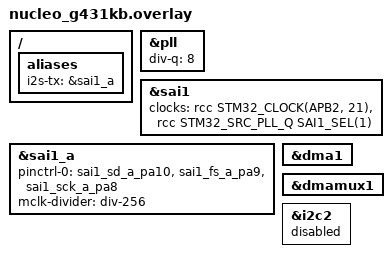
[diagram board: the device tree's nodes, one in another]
/*
 * Copyright (c) 2025 Mario Paja
 *
 * SPDX-License-Identifier: Apache-2.0
 */

/ {
	aliases {
		i2s-tx = &sai1_a;
	};
};

&pll {
	/* 44.1KHz (-0.03% Error) */
	div-q = <8>;
};

&sai1 {
	clocks = <&rcc STM32_CLOCK(APB2, 21)>,
		 <&rcc STM32_SRC_PLL_Q SAI1_SEL(1)>;
	clock-names = "sai_ck", "sai_ker_ck";
	status = "okay";
};

/* MCLK is not enabled */
/* SAI1_A MCLK (PB8) is not available on the Arduino Nano header */
&sai1_a {
	pinctrl-0 = <&sai1_sd_a_pa10 &sai1_fs_a_pa9 &sai1_sck_a_pa8>;
	pinctrl-names = "default";
	mclk-divider = "div-256";
	dma-names = "tx";
	status = "okay";
};

&dma1 {
	status = "okay";
};

&dmamux1 {
	status = "okay";
};

/* I2C2 SCL conflicts with SAI1_A FS */
/* I2C2 SDA conflicts with SAI1_A SCK */
&i2c2 {
	status = "disabled";
};
